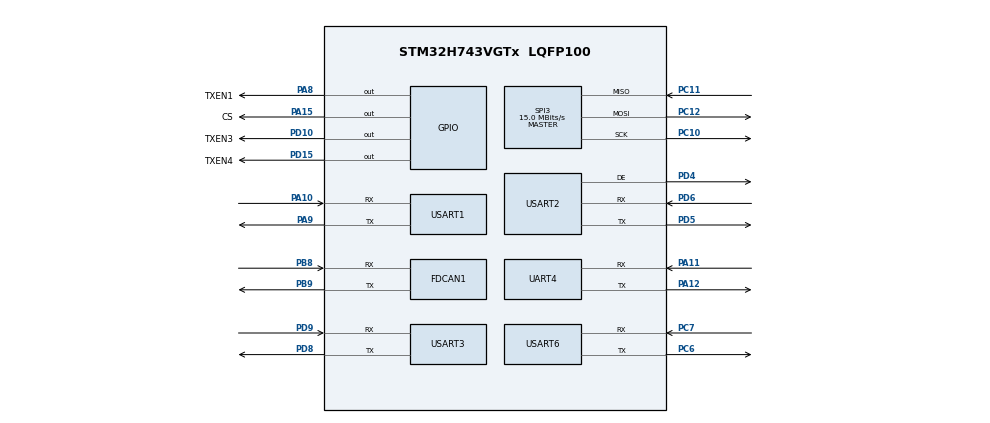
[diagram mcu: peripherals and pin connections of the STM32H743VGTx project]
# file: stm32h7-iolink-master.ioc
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Dma.Request0=USART6_RX
Dma.Request1=USART3_RX
Dma.Request2=USART2_RX
Dma.Request3=USART1_RX
Dma.Request4=USART1_TX
Dma.Request5=USART2_TX
Dma.Request6=USART3_TX
Dma.Request7=USART6_TX
Dma.USART1_RX.3.Direction=DMA_PERIPH_TO_MEMORY
Dma.USART1_RX.3.EventEnable=DISABLE
Dma.USART1_RX.3.FIFOMode=DMA_FIFOMODE_DISABLE
Dma.USART1_RX.3.Instance=DMA1_Stream3
Dma.USART1_RX.3.MemDataAlignment=DMA_MDATAALIGN_BYTE
Dma.USART1_RX.3.MemInc=DMA_MINC_ENABLE
Dma.USART1_RX.3.Mode=DMA_CIRCULAR
Dma.USART1_RX.3.PeriphDataAlignment=DMA_PDATAALIGN_BYTE
Dma.USART1_RX.3.PeriphInc=DMA_PINC_DISABLE
Dma.USART1_RX.3.Polarity=HAL_DMAMUX_REQ_GEN_RISING
Dma.USART1_RX.3.Priority=DMA_PRIORITY_LOW
Dma.USART1_RX.3.RequestNumber=1
Dma.USART1_RX.3.SignalID=NONE
Dma.USART1_RX.3.SyncEnable=DISABLE
Dma.USART1_RX.3.SyncPolarity=HAL_DMAMUX_SYNC_NO_EVENT
Dma.USART1_RX.3.SyncRequestNumber=1
Dma.USART1_RX.3.SyncSignalID=NONE
Dma.USART1_TX.4.Direction=DMA_MEMORY_TO_PERIPH
Dma.USART1_TX.4.EventEnable=DISABLE
Dma.USART1_TX.4.FIFOMode=DMA_FIFOMODE_DISABLE
Dma.USART1_TX.4.Instance=DMA1_Stream4
Dma.USART1_TX.4.MemDataAlignment=DMA_MDATAALIGN_BYTE
Dma.USART1_TX.4.MemInc=DMA_MINC_ENABLE
Dma.USART1_TX.4.Mode=DMA_NORMAL
Dma.USART1_TX.4.PeriphDataAlignment=DMA_PDATAALIGN_BYTE
Dma.USART1_TX.4.PeriphInc=DMA_PINC_DISABLE
Dma.USART1_TX.4.Polarity=HAL_DMAMUX_REQ_GEN_RISING
Dma.USART1_TX.4.Priority=DMA_PRIORITY_LOW
Dma.USART1_TX.4.RequestNumber=1
Dma.USART1_TX.4.SignalID=NONE
Dma.USART1_TX.4.SyncEnable=DISABLE
Dma.USART1_TX.4.SyncPolarity=HAL_DMAMUX_SYNC_NO_EVENT
Dma.USART1_TX.4.SyncRequestNumber=1
Dma.USART1_TX.4.SyncSignalID=NONE
Dma.USART2_RX.2.Direction=DMA_PERIPH_TO_MEMORY
Dma.USART2_RX.2.EventEnable=DISABLE
Dma.USART2_RX.2.FIFOMode=DMA_FIFOMODE_DISABLE
Dma.USART2_RX.2.Instance=DMA1_Stream2
Dma.USART2_RX.2.MemDataAlignment=DMA_MDATAALIGN_BYTE
Dma.USART2_RX.2.MemInc=DMA_MINC_ENABLE
Dma.USART2_RX.2.Mode=DMA_CIRCULAR
Dma.USART2_RX.2.PeriphDataAlignment=DMA_PDATAALIGN_BYTE
Dma.USART2_RX.2.PeriphInc=DMA_PINC_DISABLE
Dma.USART2_RX.2.Polarity=HAL_DMAMUX_REQ_GEN_RISING
Dma.USART2_RX.2.Priority=DMA_PRIORITY_LOW
Dma.USART2_RX.2.RequestNumber=1
Dma.USART2_RX.2.SignalID=NONE
Dma.USART2_RX.2.SyncEnable=DISABLE
Dma.USART2_RX.2.SyncPolarity=HAL_DMAMUX_SYNC_NO_EVENT
Dma.USART2_RX.2.SyncRequestNumber=1
Dma.USART2_RX.2.SyncSignalID=NONE
Dma.USART2_TX.5.Direction=DMA_MEMORY_TO_PERIPH
Dma.USART2_TX.5.EventEnable=DISABLE
Dma.USART2_TX.5.FIFOMode=DMA_FIFOMODE_DISABLE
Dma.USART2_TX.5.Instance=DMA1_Stream5
Dma.USART2_TX.5.MemDataAlignment=DMA_MDATAALIGN_BYTE
Dma.USART2_TX.5.MemInc=DMA_MINC_ENABLE
Dma.USART2_TX.5.Mode=DMA_NORMAL
Dma.USART2_TX.5.PeriphDataAlignment=DMA_PDATAALIGN_BYTE
Dma.USART2_TX.5.PeriphInc=DMA_PINC_DISABLE
Dma.USART2_TX.5.Polarity=HAL_DMAMUX_REQ_GEN_RISING
Dma.USART2_TX.5.Priority=DMA_PRIORITY_LOW
Dma.USART2_TX.5.RequestNumber=1
Dma.USART2_TX.5.SignalID=NONE
Dma.USART2_TX.5.SyncEnable=DISABLE
Dma.USART2_TX.5.SyncPolarity=HAL_DMAMUX_SYNC_NO_EVENT
Dma.USART2_TX.5.SyncRequestNumber=1
Dma.USART2_TX.5.SyncSignalID=NONE
Dma.USART3_RX.1.Direction=DMA_PERIPH_TO_MEMORY
Dma.USART3_RX.1.EventEnable=DISABLE
Dma.USART3_RX.1.FIFOMode=DMA_FIFOMODE_DISABLE
Dma.USART3_RX.1.Instance=DMA1_Stream1
Dma.USART3_RX.1.MemDataAlignment=DMA_MDATAALIGN_BYTE
Dma.USART3_RX.1.MemInc=DMA_MINC_ENABLE
Dma.USART3_RX.1.Mode=DMA_CIRCULAR
Dma.USART3_RX.1.PeriphDataAlignment=DMA_PDATAALIGN_BYTE
Dma.USART3_RX.1.PeriphInc=DMA_PINC_DISABLE
Dma.USART3_RX.1.Polarity=HAL_DMAMUX_REQ_GEN_RISING
Dma.USART3_RX.1.Priority=DMA_PRIORITY_LOW
Dma.USART3_RX.1.RequestNumber=1
Dma.USART3_RX.1.SignalID=NONE
Dma.USART3_RX.1.SyncEnable=DISABLE
Dma.USART3_RX.1.SyncPolarity=HAL_DMAMUX_SYNC_NO_EVENT
Dma.USART3_RX.1.SyncRequestNumber=1
Dma.USART3_RX.1.SyncSignalID=NONE
Dma.USART3_TX.6.Direction=DMA_MEMORY_TO_PERIPH
Dma.USART3_TX.6.EventEnable=DISABLE
Dma.USART3_TX.6.FIFOMode=DMA_FIFOMODE_DISABLE
Dma.USART3_TX.6.Instance=DMA1_Stream6
Dma.USART3_TX.6.MemDataAlignment=DMA_MDATAALIGN_BYTE
Dma.USART3_TX.6.MemInc=DMA_MINC_ENABLE
Dma.USART3_TX.6.Mode=DMA_NORMAL
Dma.USART3_TX.6.PeriphDataAlignment=DMA_PDATAALIGN_BYTE
Dma.USART3_TX.6.PeriphInc=DMA_PINC_DISABLE
Dma.USART3_TX.6.Polarity=HAL_DMAMUX_REQ_GEN_RISING
Dma.USART3_TX.6.Priority=DMA_PRIORITY_LOW
Dma.USART3_TX.6.RequestNumber=1
Dma.USART3_TX.6.SignalID=NONE
Dma.USART3_TX.6.SyncEnable=DISABLE
Dma.USART3_TX.6.SyncPolarity=HAL_DMAMUX_SYNC_NO_EVENT
Dma.USART3_TX.6.SyncRequestNumber=1
Dma.USART3_TX.6.SyncSignalID=NONE
Dma.USART6_RX.0.Direction=DMA_PERIPH_TO_MEMORY
Dma.USART6_RX.0.EventEnable=DISABLE
Dma.USART6_RX.0.FIFOMode=DMA_FIFOMODE_DISABLE
Dma.USART6_RX.0.Instance=DMA1_Stream0
Dma.USART6_RX.0.MemDataAlignment=DMA_MDATAALIGN_BYTE
Dma.USART6_RX.0.MemInc=DMA_MINC_ENABLE
Dma.USART6_RX.0.Mode=DMA_CIRCULAR
Dma.USART6_RX.0.PeriphDataAlignment=DMA_PDATAALIGN_BYTE
Dma.USART6_RX.0.PeriphInc=DMA_PINC_DISABLE
Dma.USART6_RX.0.Polarity=HAL_DMAMUX_REQ_GEN_RISING
Dma.USART6_RX.0.Priority=DMA_PRIORITY_LOW
Dma.USART6_RX.0.RequestNumber=1
Dma.USART6_RX.0.SignalID=NONE
Dma.USART6_RX.0.SyncEnable=DISABLE
Dma.USART6_RX.0.SyncPolarity=HAL_DMAMUX_SYNC_NO_EVENT
Dma.USART6_RX.0.SyncRequestNumber=1
Dma.USART6_RX.0.SyncSignalID=NONE
Dma.USART6_TX.7.Direction=DMA_MEMORY_TO_PERIPH
Dma.USART6_TX.7.EventEnable=DISABLE
Dma.USART6_TX.7.FIFOMode=DMA_FIFOMODE_DISABLE
Dma.USART6_TX.7.Instance=DMA1_Stream7
Dma.USART6_TX.7.MemDataAlignment=DMA_MDATAALIGN_BYTE
Dma.USART6_TX.7.MemInc=DMA_MINC_ENABLE
Dma.USART6_TX.7.Mode=DMA_NORMAL
Dma.USART6_TX.7.PeriphDataAlignment=DMA_PDATAALIGN_BYTE
Dma.USART6_TX.7.PeriphInc=DMA_PINC_DISABLE
Dma.USART6_TX.7.Polarity=HAL_DMAMUX_REQ_GEN_RISING
Dma.USART6_TX.7.Priority=DMA_PRIORITY_LOW
Dma.USART6_TX.7.RequestNumber=1
Dma.USART6_TX.7.SignalID=NONE
Dma.USART6_TX.7.SyncEnable=DISABLE
Dma.USART6_TX.7.SyncPolarity=HAL_DMAMUX_SYNC_NO_EVENT
Dma.USART6_TX.7.SyncRequestNumber=1
Dma.USART6_TX.7.SyncSignalID=NONE
FDCAN1.CalculateBaudRateNominal=1066666
FDCAN1.CalculateTimeBitNominal=937
FDCAN1.CalculateTimeQuantumNominal=62.5
FDCAN1.NominalPrescaler=2
FDCAN1.NominalTimeSeg1=13
FDCAN1.TxFifoQueueElmtsNbr=32
Mcu.Family=STM32H7
Mcu.Name=STM32H743VGTx
Mcu.Package=LQFP100
NVIC.DMA1_Stream0_IRQn=true\:0\:0\:false\:false\:true\:false\:true\:true
NVIC.DMA1_Stream1_IRQn=true\:0\:0\:false\:false\:true\:false\:true\:true
NVIC.DMA1_Stream2_IRQn=true\:0\:0\:false\:false\:true\:false\:true\:true
NVIC.DMA1_Stream3_IRQn=true\:0\:0\:false\:false\:true\:false\:true\:true
NVIC.DMA1_Stream4_IRQn=true\:0\:0\:false\:false\:true\:false\:true\:true
NVIC.DMA1_Stream5_IRQn=true\:0\:0\:false\:false\:true\:false\:true\:true
NVIC.DMA1_Stream6_IRQn=true\:0\:0\:false\:false\:true\:false\:true\:true
NVIC.DMA1_Stream7_IRQn=true\:0\:0\:false\:false\:true\:false\:true\:true
NVIC.PriorityGroup=NVIC_PRIORITYGROUP_4
NVIC.USART1_IRQn=true\:0\:0\:false\:false\:true\:true\:true\:true
NVIC.USART2_IRQn=true\:0\:0\:false\:false\:true\:true\:true\:true
NVIC.USART3_IRQn=true\:0\:0\:false\:false\:true\:true\:true\:true
NVIC.USART6_IRQn=true\:0\:0\:false\:false\:true\:true\:true\:true
PA10.Mode=Asynchronous
PA10.Signal=USART1_RX
PA11.Mode=Asynchronous
PA11.Signal=UART4_RX
PA12.Mode=Asynchronous
PA12.Signal=UART4_TX
PA13\ (JTMS/SWDIO).Mode=Serial_Wire
PA13\ (JTMS/SWDIO).Signal=DEBUG_JTMS-SWDIO
PA14\ (JTCK/SWCLK).Mode=Serial_Wire
PA14\ (JTCK/SWCLK).Signal=DEBUG_JTCK-SWCLK
PA15\ (JTDI).GPIO_Label=CS
PA15\ (JTDI).Signal=GPIO_Output
PA8.GPIO_Label=TXEN1
PA8.Signal=GPIO_Output
PA9.Mode=Asynchronous
PA9.Signal=USART1_TX
PB8.Mode=FDCAN_Activate
PB8.Signal=FDCAN1_RX
PB9.Mode=FDCAN_Activate
PB9.Signal=FDCAN1_TX
PC10.Mode=Full_Duplex_Master
PC10.Signal=SPI3_SCK
PC11.Mode=Full_Duplex_Master
PC11.Signal=SPI3_MISO
PC12.Mode=Full_Duplex_Master
PC12.Signal=SPI3_MOSI
PC6.Mode=Asynchronous
PC6.Signal=USART6_TX
PC7.Mode=Asynchronous
PC7.Signal=USART6_RX
PD10.GPIO_Label=TXEN3
PD10.Signal=GPIO_Output
PD15.GPIO_Label=TXEN4
PD15.Signal=GPIO_Output
PD4.Mode=Hardware Flow Control (RS485)
PD4.Signal=USART2_DE
PD5.Mode=Asynchronous
PD5.Signal=USART2_TX
PD6.Mode=Asynchronous
PD6.Signal=USART2_RX
PD8.Mode=Asynchronous
PD8.Signal=USART3_TX
PD9.Mode=Asynchronous
PD9.Signal=USART3_RX
PH0-OSC_IN\ (PH0).Mode=HSE-External-Oscillator
PH0-OSC_IN\ (PH0).Signal=RCC_OSC_IN
PH1-OSC_OUT\ (PH1).Mode=HSE-External-Oscillator
PH1-OSC_OUT\ (PH1).Signal=RCC_OSC_OUT
ProjectManager.HeapSize=0x200
ProjectManager.StackSize=0x400
ProjectManager.TargetToolchain=CMake
RCC.ADCFreq_Value=64500000
RCC.APB1Freq_Value=60000000
RCC.APB2Freq_Value=60000000
RCC.APB3Freq_Value=120000000
RCC.APB4Freq_Value=120000000
RCC.CortexFreq_Value=240000000
RCC.D2PPRE1=RCC_APB1_DIV2
RCC.D2PPRE2=RCC_APB2_DIV2
RCC.DIVM1=2
RCC.DIVN1=30
RCC.DIVQ1=4
RCC.FDCANCLockSelection=RCC_FDCANCLKSOURCE_HSE
RCC.HCLKFreq_Value=120000000
RCC.HPRE=RCC_HCLK_DIV2
RCC.HSE_VALUE=32000000
RCC.PLL2FRACN=0
RCC.PLL3FRACN=0
RCC.PLLFRACN=0
RCC.PLLSourceVirtual=RCC_PLLSOURCE_HSE
RCC.SYSCLKFreq_VALUE=240000000
RCC.SYSCLKSource=RCC_SYSCLKSOURCE_PLLCLK
RCC.USBFreq_Value=120000000
SPI3.BaudRatePrescaler=SPI_BAUDRATEPRESCALER_8
SPI3.CalculateBaudRate=15.0 MBits/s
SPI3.DataSize=SPI_DATASIZE_8BIT
SPI3.Direction=SPI_DIRECTION_2LINES
SPI3.Mode=SPI_MODE_MASTER
SPI3.VirtualType=VM_MASTER
TIM1.Prescaler=120-1
USART1.Parity=PARITY_EVEN
USART1.VirtualMode-Asynchronous=VM_ASYNC
USART1.WordLength=WORDLENGTH_9B
USART2.Parity=PARITY_EVEN
USART2.UART_DEPolarity=UART_DE_POLARITY_HIGH
USART2.VirtualMode-Asynchronous=VM_ASYNC
USART2.VirtualMode-Hardware\ Flow\ Control\ (RS485)=VM_ASYNC
USART2.WordLength=WORDLENGTH_9B
USART3.Parity=PARITY_EVEN
USART3.VirtualMode-Asynchronous=VM_ASYNC
USART3.WordLength=WORDLENGTH_9B
USART6.Parity=PARITY_EVEN
USART6.VirtualMode=VM_ASYNC
USART6.WordLength=WORDLENGTH_9B
VP_MEMORYMAP_VS_MEMORYMAP.Mode=CurAppReg
VP_TIM1_VS_ClockSourceINT.Mode=Internal
board=custom

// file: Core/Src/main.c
/* USER CODE BEGIN Header */
/**
  ******************************************************************************
  * @file           : main.c
  * @brief          : Main program body
  ******************************************************************************
  * @attention
  *
  * Copyright (c) 2025 STMicroelectronics.
  * All rights reserved.
  *
  * This software is licensed under terms that can be found in the LICENSE file
  * in the root directory of this software component.
  * If no LICENSE file comes with this software, it is provided AS-IS.
  *
  ******************************************************************************
  */
/* USER CODE END Header */
#include "main.h"

FDCAN_HandleTypeDef hfdcan1;

SPI_HandleTypeDef hspi3;

TIM_HandleTypeDef htim1;

UART_HandleTypeDef huart4;
UART_HandleTypeDef huart1;
UART_HandleTypeDef huart2;
UART_HandleTypeDef huart3;
UART_HandleTypeDef huart6;
DMA_HandleTypeDef hdma_usart1_rx;
DMA_HandleTypeDef hdma_usart1_tx;
DMA_HandleTypeDef hdma_usart2_rx;
DMA_HandleTypeDef hdma_usart2_tx;
DMA_HandleTypeDef hdma_usart3_rx;
DMA_HandleTypeDef hdma_usart3_tx;
DMA_HandleTypeDef hdma_usart6_rx;
DMA_HandleTypeDef hdma_usart6_tx;

void SystemClock_Config(void);
static void MX_GPIO_Init(void);
static void MX_DMA_Init(void);
static void MX_UART4_Init(void);
static void MX_USART1_UART_Init(void);
static void MX_USART2_UART_Init(void);
static void MX_USART3_UART_Init(void);
static void MX_USART6_UART_Init(void);
static void MX_FDCAN1_Init(void);
static void MX_SPI3_Init(void);
static void MX_TIM1_Init(void);
/* USER CODE BEGIN PFP */
void iolink_main(void);
/* USER CODE END PFP */

int main(void)
{

  /* MCU Configuration--------------------------------------------------------*/

  /* Reset of all peripherals, Initializes the Flash interface and the Systick. */
  HAL_Init();

  /* Configure the system clock */
  SystemClock_Config();

  /* Initialize all configured peripherals */
  MX_GPIO_Init();
  MX_DMA_Init();
  MX_UART4_Init();
  MX_USART1_UART_Init();
  MX_USART2_UART_Init();
  MX_USART3_UART_Init();
  MX_USART6_UART_Init();
  MX_FDCAN1_Init();
  MX_SPI3_Init();
  MX_TIM1_Init();
  /* USER CODE BEGIN 2 */
  iolink_main();
  /* USER CODE END 2 */

  /* Infinite loop */
  while (1)
  {

  }
}

void SystemClock_Config(void)
{
  RCC_OscInitTypeDef RCC_OscInitStruct = {0};
  RCC_ClkInitTypeDef RCC_ClkInitStruct = {0};

  /** Supply configuration update enable
  */
  HAL_PWREx_ConfigSupply(PWR_LDO_SUPPLY);

  /** Configure the main internal regulator output voltage
  */
  __HAL_PWR_VOLTAGESCALING_CONFIG(PWR_REGULATOR_VOLTAGE_SCALE2);

  while(!__HAL_PWR_GET_FLAG(PWR_FLAG_VOSRDY)) {}

  /** Initializes the RCC Oscillators according to the specified parameters
  * in the RCC_OscInitTypeDef structure.
  */
  RCC_OscInitStruct.OscillatorType = RCC_OSCILLATORTYPE_HSE;
  RCC_OscInitStruct.HSEState = RCC_HSE_ON;
  RCC_OscInitStruct.PLL.PLLState = RCC_PLL_ON;
  RCC_OscInitStruct.PLL.PLLSource = RCC_PLLSOURCE_HSE;
  RCC_OscInitStruct.PLL.PLLM = 2;
  RCC_OscInitStruct.PLL.PLLN = 30;
  RCC_OscInitStruct.PLL.PLLP = 2;
  RCC_OscInitStruct.PLL.PLLQ = 4;
  RCC_OscInitStruct.PLL.PLLR = 2;
  RCC_OscInitStruct.PLL.PLLRGE = RCC_PLL1VCIRANGE_3;
  RCC_OscInitStruct.PLL.PLLVCOSEL = RCC_PLL1VCOWIDE;
  RCC_OscInitStruct.PLL.PLLFRACN = 0;
  if (HAL_RCC_OscConfig(&RCC_OscInitStruct) != HAL_OK)
  {
    Error_Handler();
  }

  /** Initializes the CPU, AHB and APB buses clocks
  */
  RCC_ClkInitStruct.ClockType = RCC_CLOCKTYPE_HCLK|RCC_CLOCKTYPE_SYSCLK
                              |RCC_CLOCKTYPE_PCLK1|RCC_CLOCKTYPE_PCLK2
                              |RCC_CLOCKTYPE_D3PCLK1|RCC_CLOCKTYPE_D1PCLK1;
  RCC_ClkInitStruct.SYSCLKSource = RCC_SYSCLKSOURCE_PLLCLK;
  RCC_ClkInitStruct.SYSCLKDivider = RCC_SYSCLK_DIV1;
  RCC_ClkInitStruct.AHBCLKDivider = RCC_HCLK_DIV2;
  RCC_ClkInitStruct.APB3CLKDivider = RCC_APB3_DIV1;
  RCC_ClkInitStruct.APB1CLKDivider = RCC_APB1_DIV2;
  RCC_ClkInitStruct.APB2CLKDivider = RCC_APB2_DIV2;
  RCC_ClkInitStruct.APB4CLKDivider = RCC_APB4_DIV1;

  if (HAL_RCC_ClockConfig(&RCC_ClkInitStruct, FLASH_LATENCY_2) != HAL_OK)
  {
    Error_Handler();
  }
}

static void MX_FDCAN1_Init(void)
{

  hfdcan1.Instance = FDCAN1;
  hfdcan1.Init.FrameFormat = FDCAN_FRAME_CLASSIC;
  hfdcan1.Init.Mode = FDCAN_MODE_NORMAL;
  hfdcan1.Init.AutoRetransmission = DISABLE;
  hfdcan1.Init.TransmitPause = DISABLE;
  hfdcan1.Init.ProtocolException = DISABLE;
  hfdcan1.Init.NominalPrescaler = 2;
  hfdcan1.Init.NominalSyncJumpWidth = 1;
  hfdcan1.Init.NominalTimeSeg1 = 13;
  hfdcan1.Init.NominalTimeSeg2 = 1;
  hfdcan1.Init.DataPrescaler = 1;
  hfdcan1.Init.DataSyncJumpWidth = 1;
  hfdcan1.Init.DataTimeSeg1 = 1;
  hfdcan1.Init.DataTimeSeg2 = 1;
  hfdcan1.Init.MessageRAMOffset = 0;
  hfdcan1.Init.StdFiltersNbr = 0;
  hfdcan1.Init.ExtFiltersNbr = 0;
  hfdcan1.Init.RxFifo0ElmtsNbr = 0;
  hfdcan1.Init.RxFifo0ElmtSize = FDCAN_DATA_BYTES_8;
  hfdcan1.Init.RxFifo1ElmtsNbr = 0;
  hfdcan1.Init.RxFifo1ElmtSize = FDCAN_DATA_BYTES_8;
  hfdcan1.Init.RxBuffersNbr = 0;
  hfdcan1.Init.RxBufferSize = FDCAN_DATA_BYTES_8;
  hfdcan1.Init.TxEventsNbr = 0;
  hfdcan1.Init.TxBuffersNbr = 0;
  hfdcan1.Init.TxFifoQueueElmtsNbr = 32;
  hfdcan1.Init.TxFifoQueueMode = FDCAN_TX_FIFO_OPERATION;
  hfdcan1.Init.TxElmtSize = FDCAN_DATA_BYTES_8;
  if (HAL_FDCAN_Init(&hfdcan1) != HAL_OK)
  {
    Error_Handler();
  }

}

static void MX_SPI3_Init(void)
{

  /* SPI3 parameter configuration*/
  hspi3.Instance = SPI3;
  hspi3.Init.Mode = SPI_MODE_MASTER;
  hspi3.Init.Direction = SPI_DIRECTION_2LINES;
  hspi3.Init.DataSize = SPI_DATASIZE_8BIT;
  hspi3.Init.CLKPolarity = SPI_POLARITY_LOW;
  hspi3.Init.CLKPhase = SPI_PHASE_1EDGE;
  hspi3.Init.NSS = SPI_NSS_SOFT;
  hspi3.Init.BaudRatePrescaler = SPI_BAUDRATEPRESCALER_8;
  hspi3.Init.FirstBit = SPI_FIRSTBIT_MSB;
  hspi3.Init.TIMode = SPI_TIMODE_DISABLE;
  hspi3.Init.CRCCalculation = SPI_CRCCALCULATION_DISABLE;
  hspi3.Init.CRCPolynomial = 0x0;
  hspi3.Init.NSSPMode = SPI_NSS_PULSE_ENABLE;
  hspi3.Init.NSSPolarity = SPI_NSS_POLARITY_LOW;
  hspi3.Init.FifoThreshold = SPI_FIFO_THRESHOLD_01DATA;
  hspi3.Init.TxCRCInitializationPattern = SPI_CRC_INITIALIZATION_ALL_ZERO_PATTERN;
  hspi3.Init.RxCRCInitializationPattern = SPI_CRC_INITIALIZATION_ALL_ZERO_PATTERN;
  hspi3.Init.MasterSSIdleness = SPI_MASTER_SS_IDLENESS_00CYCLE;
  hspi3.Init.MasterInterDataIdleness = SPI_MASTER_INTERDATA_IDLENESS_00CYCLE;
  hspi3.Init.MasterReceiverAutoSusp = SPI_MASTER_RX_AUTOSUSP_DISABLE;
  hspi3.Init.MasterKeepIOState = SPI_MASTER_KEEP_IO_STATE_DISABLE;
  hspi3.Init.IOSwap = SPI_IO_SWAP_DISABLE;
  if (HAL_SPI_Init(&hspi3) != HAL_OK)
  {
    Error_Handler();
  }

}

static void MX_TIM1_Init(void)
{

  TIM_ClockConfigTypeDef sClockSourceConfig = {0};
  TIM_MasterConfigTypeDef sMasterConfig = {0};

  htim1.Instance = TIM1;
  htim1.Init.Prescaler = 120-1;
  htim1.Init.CounterMode = TIM_COUNTERMODE_UP;
  htim1.Init.Period = 65535;
  htim1.Init.ClockDivision = TIM_CLOCKDIVISION_DIV1;
  htim1.Init.RepetitionCounter = 0;
  htim1.Init.AutoReloadPreload = TIM_AUTORELOAD_PRELOAD_DISABLE;
  if (HAL_TIM_Base_Init(&htim1) != HAL_OK)
  {
    Error_Handler();
  }
  sClockSourceConfig.ClockSource = TIM_CLOCKSOURCE_INTERNAL;
  if (HAL_TIM_ConfigClockSource(&htim1, &sClockSourceConfig) != HAL_OK)
  {
    Error_Handler();
  }
  sMasterConfig.MasterOutputTrigger = TIM_TRGO_RESET;
  sMasterConfig.MasterOutputTrigger2 = TIM_TRGO2_RESET;
  sMasterConfig.MasterSlaveMode = TIM_MASTERSLAVEMODE_DISABLE;
  if (HAL_TIMEx_MasterConfigSynchronization(&htim1, &sMasterConfig) != HAL_OK)
  {
    Error_Handler();
  }

}

static void MX_UART4_Init(void)
{

  huart4.Instance = UART4;
  huart4.Init.BaudRate = 115200;
  huart4.Init.WordLength = UART_WORDLENGTH_8B;
  huart4.Init.StopBits = UART_STOPBITS_1;
  huart4.Init.Parity = UART_PARITY_NONE;
  huart4.Init.Mode = UART_MODE_TX_RX;
  huart4.Init.HwFlowCtl = UART_HWCONTROL_NONE;
  huart4.Init.OverSampling = UART_OVERSAMPLING_16;
  huart4.Init.OneBitSampling = UART_ONE_BIT_SAMPLE_DISABLE;
  huart4.Init.ClockPrescaler = UART_PRESCALER_DIV1;
  huart4.AdvancedInit.AdvFeatureInit = UART_ADVFEATURE_NO_INIT;
  if (HAL_UART_Init(&huart4) != HAL_OK)
  {
    Error_Handler();
  }
  if (HAL_UARTEx_SetTxFifoThreshold(&huart4, UART_TXFIFO_THRESHOLD_1_8) != HAL_OK)
  {
    Error_Handler();
  }
  if (HAL_UARTEx_SetRxFifoThreshold(&huart4, UART_RXFIFO_THRESHOLD_1_8) != HAL_OK)
  {
    Error_Handler();
  }
  if (HAL_UARTEx_DisableFifoMode(&huart4) != HAL_OK)
  {
    Error_Handler();
  }

}

static void MX_USART1_UART_Init(void)
{

  huart1.Instance = USART1;
  huart1.Init.BaudRate = 115200;
  huart1.Init.WordLength = UART_WORDLENGTH_9B;
  huart1.Init.StopBits = UART_STOPBITS_1;
  huart1.Init.Parity = UART_PARITY_EVEN;
  huart1.Init.Mode = UART_MODE_TX_RX;
  huart1.Init.HwFlowCtl = UART_HWCONTROL_NONE;
  huart1.Init.OverSampling = UART_OVERSAMPLING_16;
  huart1.Init.OneBitSampling = UART_ONE_BIT_SAMPLE_DISABLE;
  huart1.Init.ClockPrescaler = UART_PRESCALER_DIV1;
  huart1.AdvancedInit.AdvFeatureInit = UART_ADVFEATURE_NO_INIT;
  if (HAL_UART_Init(&huart1) != HAL_OK)
  {
    Error_Handler();
  }
  if (HAL_UARTEx_SetTxFifoThreshold(&huart1, UART_TXFIFO_THRESHOLD_1_8) != HAL_OK)
  {
    Error_Handler();
  }
  if (HAL_UARTEx_SetRxFifoThreshold(&huart1, UART_RXFIFO_THRESHOLD_1_8) != HAL_OK)
  {
    Error_Handler();
  }
  if (HAL_UARTEx_DisableFifoMode(&huart1) != HAL_OK)
  {
    Error_Handler();
  }

}

static void MX_USART2_UART_Init(void)
{

  huart2.Instance = USART2;
  huart2.Init.BaudRate = 115200;
  huart2.Init.WordLength = UART_WORDLENGTH_9B;
  huart2.Init.StopBits = UART_STOPBITS_1;
  huart2.Init.Parity = UART_PARITY_EVEN;
  huart2.Init.Mode = UART_MODE_TX_RX;
  huart2.Init.HwFlowCtl = UART_HWCONTROL_NONE;
  huart2.Init.OverSampling = UART_OVERSAMPLING_16;
  huart2.Init.OneBitSampling = UART_ONE_BIT_SAMPLE_DISABLE;
  huart2.Init.ClockPrescaler = UART_PRESCALER_DIV1;
  huart2.AdvancedInit.AdvFeatureInit = UART_ADVFEATURE_NO_INIT;
  if (HAL_RS485Ex_Init(&huart2, UART_DE_POLARITY_HIGH, 0, 0) != HAL_OK)
  {
    Error_Handler();
  }
  if (HAL_UARTEx_SetTxFifoThreshold(&huart2, UART_TXFIFO_THRESHOLD_1_8) != HAL_OK)
  {
    Error_Handler();
  }
  if (HAL_UARTEx_SetRxFifoThreshold(&huart2, UART_RXFIFO_THRESHOLD_1_8) != HAL_OK)
  {
    Error_Handler();
  }
  if (HAL_UARTEx_DisableFifoMode(&huart2) != HAL_OK)
  {
    Error_Handler();
  }

}

static void MX_USART3_UART_Init(void)
{

  huart3.Instance = USART3;
  huart3.Init.BaudRate = 115200;
  huart3.Init.WordLength = UART_WORDLENGTH_9B;
  huart3.Init.StopBits = UART_STOPBITS_1;
  huart3.Init.Parity = UART_PARITY_EVEN;
  huart3.Init.Mode = UART_MODE_TX_RX;
  huart3.Init.HwFlowCtl = UART_HWCONTROL_NONE;
  huart3.Init.OverSampling = UART_OVERSAMPLING_16;
  huart3.Init.OneBitSampling = UART_ONE_BIT_SAMPLE_DISABLE;
  huart3.Init.ClockPrescaler = UART_PRESCALER_DIV1;
  huart3.AdvancedInit.AdvFeatureInit = UART_ADVFEATURE_NO_INIT;
  if (HAL_UART_Init(&huart3) != HAL_OK)
  {
    Error_Handler();
  }
  if (HAL_UARTEx_SetTxFifoThreshold(&huart3, UART_TXFIFO_THRESHOLD_1_8) != HAL_OK)
  {
    Error_Handler();
  }
  if (HAL_UARTEx_SetRxFifoThreshold(&huart3, UART_RXFIFO_THRESHOLD_1_8) != HAL_OK)
  {
    Error_Handler();
  }
  if (HAL_UARTEx_DisableFifoMode(&huart3) != HAL_OK)
  {
    Error_Handler();
  }

}

static void MX_USART6_UART_Init(void)
{

  huart6.Instance = USART6;
  huart6.Init.BaudRate = 115200;
  huart6.Init.WordLength = UART_WORDLENGTH_9B;
  huart6.Init.StopBits = UART_STOPBITS_1;
  huart6.Init.Parity = UART_PARITY_EVEN;
  huart6.Init.Mode = UART_MODE_TX_RX;
  huart6.Init.HwFlowCtl = UART_HWCONTROL_NONE;
  huart6.Init.OverSampling = UART_OVERSAMPLING_16;
  huart6.Init.OneBitSampling = UART_ONE_BIT_SAMPLE_DISABLE;
  huart6.Init.ClockPrescaler = UART_PRESCALER_DIV1;
  huart6.AdvancedInit.AdvFeatureInit = UART_ADVFEATURE_NO_INIT;
  if (HAL_UART_Init(&huart6) != HAL_OK)
  {
    Error_Handler();
  }
  if (HAL_UARTEx_SetTxFifoThreshold(&huart6, UART_TXFIFO_THRESHOLD_1_8) != HAL_OK)
  {
    Error_Handler();
  }
  if (HAL_UARTEx_SetRxFifoThreshold(&huart6, UART_RXFIFO_THRESHOLD_1_8) != HAL_OK)
  {
    Error_Handler();
  }
  if (HAL_UARTEx_DisableFifoMode(&huart6) != HAL_OK)
  {
    Error_Handler();
  }

}

static void MX_DMA_Init(void)
{

  /* DMA controller clock enable */
  __HAL_RCC_DMA1_CLK_ENABLE();

  /* DMA interrupt init */
  /* DMA1_Stream0_IRQn interrupt configuration */
  HAL_NVIC_SetPriority(DMA1_Stream0_IRQn, 0, 0);
  HAL_NVIC_EnableIRQ(DMA1_Stream0_IRQn);
  /* DMA1_Stream1_IRQn interrupt configuration */
  HAL_NVIC_SetPriority(DMA1_Stream1_IRQn, 0, 0);
  HAL_NVIC_EnableIRQ(DMA1_Stream1_IRQn);
  /* DMA1_Stream2_IRQn interrupt configuration */
  HAL_NVIC_SetPriority(DMA1_Stream2_IRQn, 0, 0);
  HAL_NVIC_EnableIRQ(DMA1_Stream2_IRQn);
  /* DMA1_Stream3_IRQn interrupt configuration */
  HAL_NVIC_SetPriority(DMA1_Stream3_IRQn, 0, 0);
  HAL_NVIC_EnableIRQ(DMA1_Stream3_IRQn);
  /* DMA1_Stream4_IRQn interrupt configuration */
  HAL_NVIC_SetPriority(DMA1_Stream4_IRQn, 0, 0);
  HAL_NVIC_EnableIRQ(DMA1_Stream4_IRQn);
  /* DMA1_Stream5_IRQn interrupt configuration */
  HAL_NVIC_SetPriority(DMA1_Stream5_IRQn, 0, 0);
  HAL_NVIC_EnableIRQ(DMA1_Stream5_IRQn);
  /* DMA1_Stream6_IRQn interrupt configuration */
  HAL_NVIC_SetPriority(DMA1_Stream6_IRQn, 0, 0);
  HAL_NVIC_EnableIRQ(DMA1_Stream6_IRQn);
  /* DMA1_Stream7_IRQn interrupt configuration */
  HAL_NVIC_SetPriority(DMA1_Stream7_IRQn, 0, 0);
  HAL_NVIC_EnableIRQ(DMA1_Stream7_IRQn);

}

static void MX_GPIO_Init(void)
{
  GPIO_InitTypeDef GPIO_InitStruct = {0};

  /* GPIO Ports Clock Enable */
  __HAL_RCC_GPIOH_CLK_ENABLE();
  __HAL_RCC_GPIOD_CLK_ENABLE();
  __HAL_RCC_GPIOC_CLK_ENABLE();
  __HAL_RCC_GPIOA_CLK_ENABLE();
  __HAL_RCC_GPIOB_CLK_ENABLE();

  /*Configure GPIO pin Output Level */
  HAL_GPIO_WritePin(GPIOD, TXEN3_Pin|TXEN4_Pin, GPIO_PIN_RESET);

  /*Configure GPIO pin Output Level */
  HAL_GPIO_WritePin(GPIOA, TXEN1_Pin|CS_Pin, GPIO_PIN_RESET);

  /*Configure GPIO pins : TXEN3_Pin TXEN4_Pin */
  GPIO_InitStruct.Pin = TXEN3_Pin|TXEN4_Pin;
  GPIO_InitStruct.Mode = GPIO_MODE_OUTPUT_PP;
  GPIO_InitStruct.Pull = GPIO_NOPULL;
  GPIO_InitStruct.Speed = GPIO_SPEED_FREQ_LOW;
  HAL_GPIO_Init(GPIOD, &GPIO_InitStruct);

  /*Configure GPIO pins : TXEN1_Pin CS_Pin */
  GPIO_InitStruct.Pin = TXEN1_Pin|CS_Pin;
  GPIO_InitStruct.Mode = GPIO_MODE_OUTPUT_PP;
  GPIO_InitStruct.Pull = GPIO_NOPULL;
  GPIO_InitStruct.Speed = GPIO_SPEED_FREQ_LOW;
  HAL_GPIO_Init(GPIOA, &GPIO_InitStruct);

}

void Error_Handler(void)
{
  __disable_irq();
  while (1)
  {
  }
}
